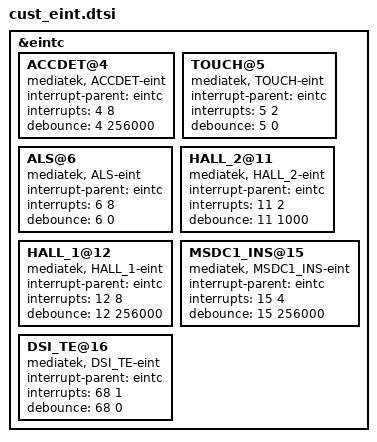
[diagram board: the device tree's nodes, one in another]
/*
 * Generated by MTK SP DrvGen Version 03.13.6 for MT6580. Copyright MediaTek Inc. (C) 2013.
 * Thu Aug 09 08:52:55 2018
 * Do Not Modify the File.
 */

/*************************
 * EINT DTSI File
*************************/

&eintc {
	ACCDET@4 {
		compatible = "mediatek, ACCDET-eint";
		interrupt-parent = <&eintc>;
		interrupts = <4 8>;
		debounce = <4 256000>;
	};

	TOUCH@5 {
		compatible = "mediatek, TOUCH-eint";
		interrupt-parent = <&eintc>;
		interrupts = <5 2>;
		debounce = <5 0>;
	};

	ALS@6 {
		compatible = "mediatek, ALS-eint";
		interrupt-parent = <&eintc>;
		interrupts = <6 8>;
		debounce = <6 0>;
	};

	HALL_2@11 {
		compatible = "mediatek, HALL_2-eint";
		interrupt-parent = <&eintc>;
		interrupts = <11 2>;
		debounce = <11 1000>;
	};

	HALL_1@12 {
		compatible = "mediatek, HALL_1-eint";
		interrupt-parent = <&eintc>;
		interrupts = <12 8>;
		debounce = <12 256000>;
	};

	MSDC1_INS@15 {
		compatible = "mediatek, MSDC1_INS-eint";
		interrupt-parent = <&eintc>;
		interrupts = <15 4>;
		debounce = <15 256000>;
	};

	DSI_TE@16 {
		compatible = "mediatek, DSI_TE-eint";
		interrupt-parent = <&eintc>;
		interrupts = <68 1>;
		debounce = <68 0>;
	};

};
